# HDSC_HC32L176KATA register map
Vendor: HDSC Co.Ltd; Series: ARMCM0P; File version: 1.2
CPU: CM0 r0p0, little endian, no MPU, no FPU, 3 interrupt priority bits
Registers are 32-bit, read-write, reset 0x0 unless marked. A register's access mark holds for its fields unless they carry their own. Offsets are from the block's base; [hi:lo] are bit positions; {n}, {i} and the like mark numbered series.

## LCD
Base 0x40005C00
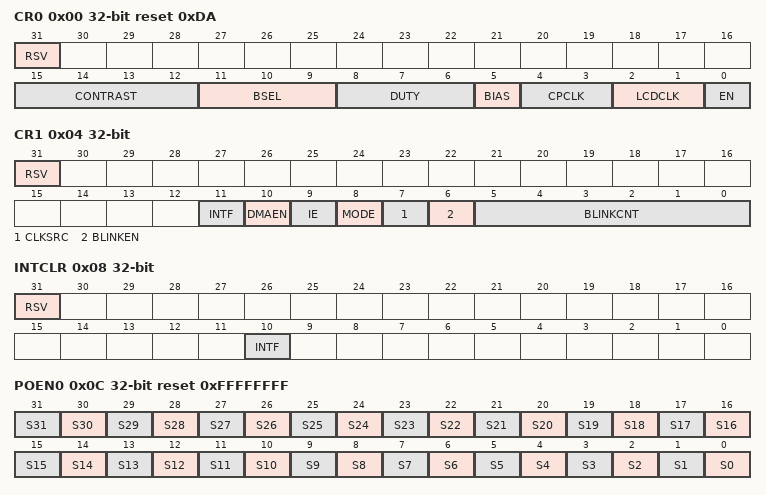
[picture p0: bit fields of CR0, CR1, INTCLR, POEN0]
0x00 CR0 reset 0xDA (reset mask 0xFF)
  [31] RSV, [15:12] CONTRAST, [11:9] BSEL, [8:6] DUTY, [5] BIAS, [4:3] CPCLK, [2:1] LCDCLK, [0] EN
0x04 CR1 (reset mask 0xFFF)
  [31] RSV ro, [11] INTF ro, [10] DMAEN, [9] IE, [8] MODE, [7] CLKSRC, [6] BLINKEN, [5:0] BLINKCNT
0x08 INTCLR wo (reset mask 0x400)
  [31] RSV rw, [10] INTF
0x0C POEN0 reset 0xFFFFFFFF
  [n] S{n} (n=0..31)
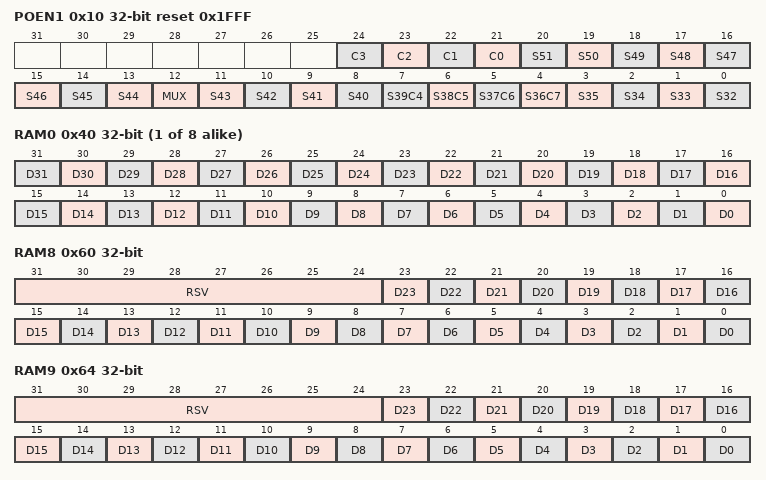
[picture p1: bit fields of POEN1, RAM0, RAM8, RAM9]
0x10 POEN1 reset 0x1FFF (reset mask 0x1FFF)
  [n+21] C{n} (n=0..3), [n-31] S{n} (n=44..51), [12] MUX, [n-32] S{n} (n=40..43), [7] S39C4, [6] S38C5, [5] S37C6, [4] S36C7, [n-32] S{n} (n=32..35)
{0x40+4i} RAM{i} (i=0..7)
  [n] D{n} (n=0..31)
0x60 RAM8 (reset mask 0xFFFFFF)
  [31:24] RSV, [n] D{n} (n=0..23)
0x64 RAM9 (reset mask 0xFFFFFF)
  [31:24] RSV, [n] D{n} (n=0..23)
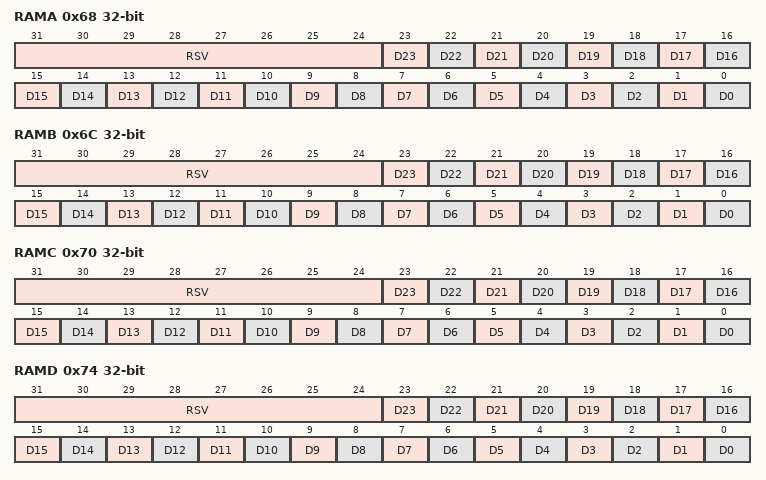
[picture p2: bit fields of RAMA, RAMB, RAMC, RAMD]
0x68 RAMA (reset mask 0xFFFFFF)
  [31:24] RSV, [n] D{n} (n=0..23)
0x6C RAMB (reset mask 0xFFFFFF)
  [31:24] RSV, [n] D{n} (n=0..23)
0x70 RAMC (reset mask 0xFFFFFF)
  [31:24] RSV, [n] D{n} (n=0..23)
0x74 RAMD (reset mask 0xFFFFFF)
  [31:24] RSV, [n] D{n} (n=0..23)
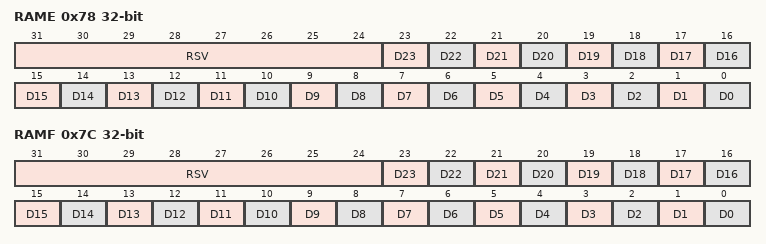
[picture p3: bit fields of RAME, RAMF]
0x78 RAME (reset mask 0xFFFFFF)
  [31:24] RSV, [n] D{n} (n=0..23)
0x7C RAMF (reset mask 0xFFFFFF)
  [31:24] RSV, [n] D{n} (n=0..23)

## LPTIMER0 — desc LPTIMER
Base 0x40000F00
Same registers: LPTIMER1 0x40000F40
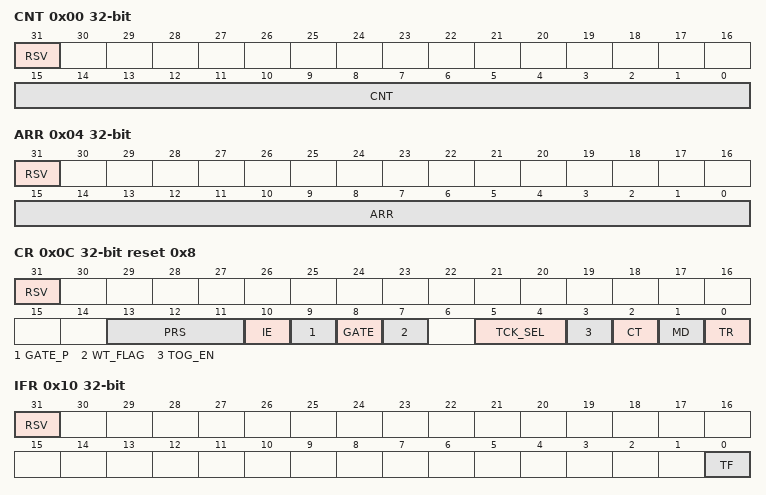
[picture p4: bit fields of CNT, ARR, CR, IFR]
0x00 CNT ro (reset mask 0xFFFF)
  [31] RSV rw, [15:0] CNT
0x04 ARR (reset mask 0xFFFF)
  [31] RSV, [15:0] ARR
0x0C CR reset 0x8 (reset mask 0x3FBF)
  [31] RSV, [13:11] PRS, [10] IE, [9] GATE_P, [8] GATE, [7] WT_FLAG ro, [5:4] TCK_SEL, [3] TOG_EN, [2] CT, [1] MD, [0] TR
0x10 IFR ro (reset mask 0x1)
  [31] RSV rw, [0] TF
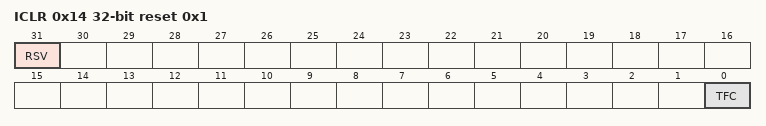
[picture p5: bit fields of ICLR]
0x14 ICLR wo reset 0x1 (reset mask 0x1)
  [31] RSV rw, [0] TFC

## LPUART0 — desc LPUART
Base 0x40000200
Same registers: LPUART1 0x40004000
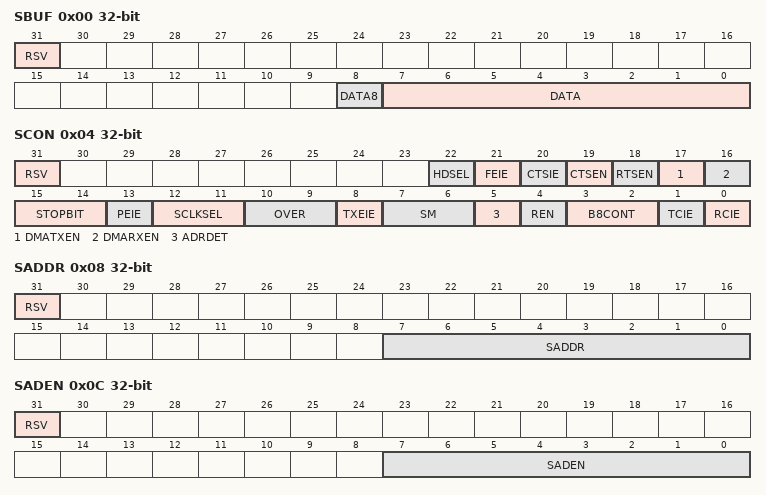
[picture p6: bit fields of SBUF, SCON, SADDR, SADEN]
0x00 SBUF (reset mask 0x1FF)
  [31] RSV, [8] DATA8, [7:0] DATA
0x04 SCON (reset mask 0x7FFFFF)
  [31] RSV, [22] HDSEL, [21] FEIE, [20] CTSIE, [19] CTSEN, [18] RTSEN, [17] DMATXEN, [16] DMARXEN, [15:14] STOPBIT, [13] PEIE, [12:11] SCLKSEL, [10:9] OVER, [8] TXEIE, [7:6] SM, [5] ADRDET, [4] REN, [3:2] B8CONT, [1] TCIE, [0] RCIE
0x08 SADDR (reset mask 0xFF)
  [31] RSV, [7:0] SADDR
0x0C SADEN (reset mask 0xFF)
  [31] RSV, [7:0] SADEN
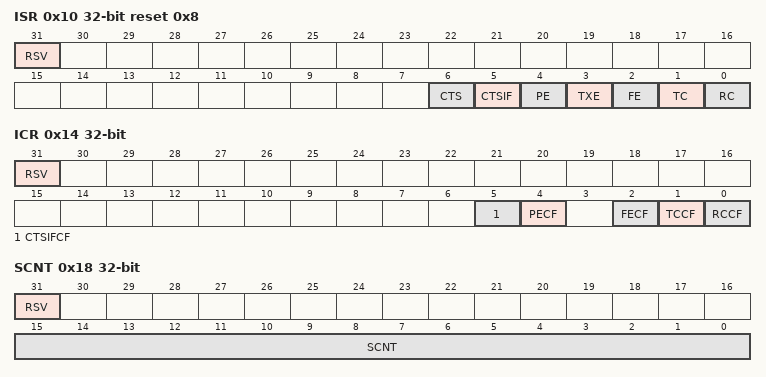
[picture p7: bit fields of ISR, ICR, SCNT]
0x10 ISR ro reset 0x8 (reset mask 0x7F)
  [31] RSV rw, [6] CTS, [5] CTSIF, [4] PE, [3] TXE, [2] FE, [1] TC, [0] RC
0x14 ICR wo (reset mask 0x37)
  [31] RSV rw, [5] CTSIFCF, [4] PECF, [2] FECF, [1] TCCF, [0] RCCF
0x18 SCNT (reset mask 0xFFFF)
  [31] RSV, [15:0] SCNT

## UART0 — desc UART
Base 0x40000000
Same registers: UART1 0x40000100, UART2 0x40006000, UART3 0x40006400
Registers as LPUART0; these are added or differ:
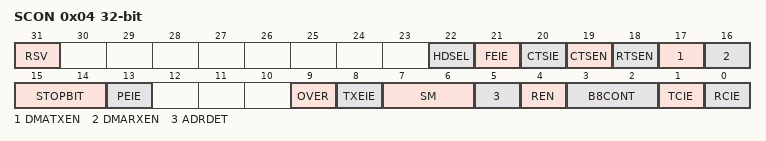
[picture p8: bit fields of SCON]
0x04 SCON (reset mask 0x7FE3FF)
  [31] RSV, [22] HDSEL, [21] FEIE, [20] CTSIE, [19] CTSEN, [18] RTSEN, [17] DMATXEN, [16] DMARXEN, [15:14] STOPBIT, [13] PEIE, [9] OVER, [8] TXEIE, [7:6] SM, [5] ADRDET, [4] REN, [3:2] B8CONT, [1] TCIE, [0] RCIE

## LVD
Base 0x40002400; alternate view of ADC
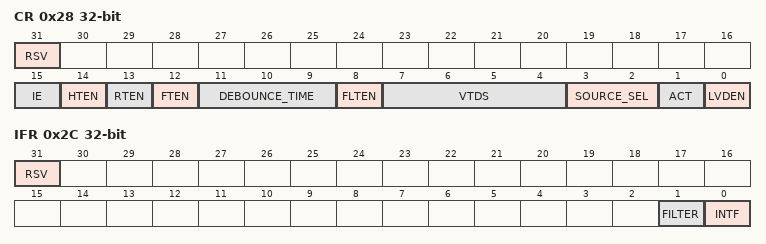
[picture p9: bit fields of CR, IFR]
0x28 CR (reset mask 0xFFFF)
  [31] RSV, [15] IE, [14] HTEN, [13] RTEN, [12] FTEN, [11:9] DEBOUNCE_TIME, [8] FLTEN, [7:4] VTDS, [3:2] SOURCE_SEL, [1] ACT, [0] LVDEN
0x2C IFR (reset mask 0x3)
  [31] RSV, [1] FILTER, [0] INTF

## OPA
Base 0x40002400; alternate view of ADC
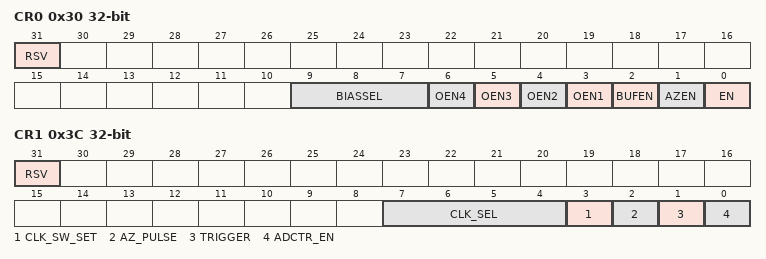
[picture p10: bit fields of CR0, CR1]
0x30 CR0 (reset mask 0xFFF)
  [31] RSV, [9:7] BIASSEL, [n+2] OEN{n} (n=1..4), [2] BUFEN, [1] AZEN, [0] EN
0x3C CR1 (reset mask 0xFF)
  [31] RSV, [7:4] CLK_SEL, [3] CLK_SW_SET, [2] AZ_PULSE, [1] TRIGGER, [0] ADCTR_EN

## PCA
Base 0x40001000
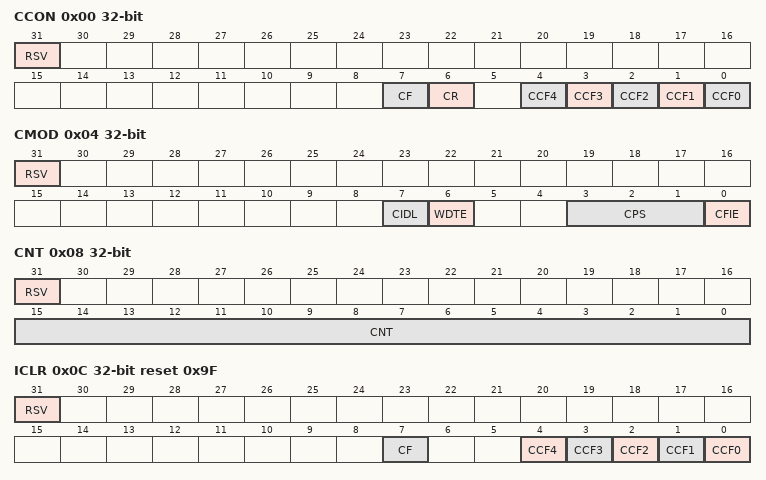
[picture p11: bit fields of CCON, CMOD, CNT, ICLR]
0x00 CCON (reset mask 0xDF)
  [31] RSV, [7] CF, [6] CR, [n] CCF{n} (n=0..4)
0x04 CMOD (reset mask 0xCF)
  [31] RSV, [7] CIDL, [6] WDTE, [3:1] CPS, [0] CFIE
0x08 CNT (reset mask 0xFFFF)
  [31] RSV, [15:0] CNT
0x0C ICLR wo reset 0x9F (reset mask 0x9F)
  [31] RSV rw, [7] CF, [n] CCF{n} (n=0..4)
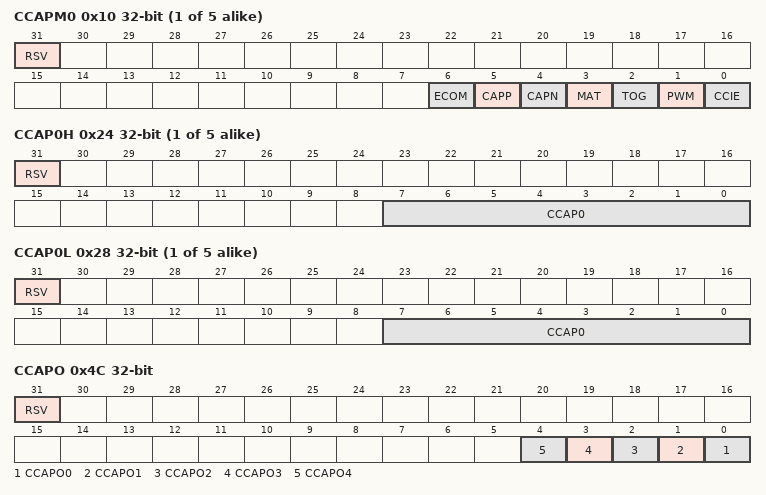
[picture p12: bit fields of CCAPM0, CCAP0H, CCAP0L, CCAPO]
{0x10+4i} CCAPM{i} (reset mask 0x7F) (i=0..4)
  [31] RSV, [6] ECOM, [5] CAPP, [4] CAPN, [3] MAT, [2] TOG, [1] PWM, [0] CCIE
{0x24+8i} CCAP{i}H (reset mask 0xFF) (i=0..4)
  [31] RSV, [7:0] CCAP{i}
{0x28+8i} CCAP{i}L (reset mask 0xFF) (i=0..4)
  [31] RSV, [7:0] CCAP{i}
0x4C CCAPO (reset mask 0x1F)
  [31] RSV, [n] CCAPO{n} (n=0..4)
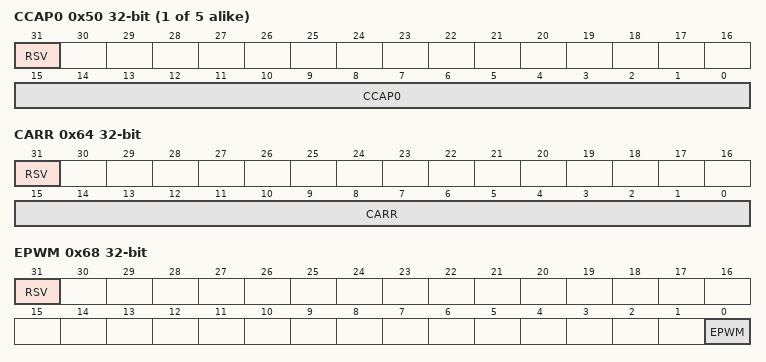
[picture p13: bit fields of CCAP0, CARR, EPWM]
{0x50+4i} CCAP{i} (reset mask 0xFFFF) (i=0..4)
  [31] RSV, [15:0] CCAP{i}
0x64 CARR (reset mask 0xFFFF)
  [31] RSV, [15:0] CARR
0x68 EPWM (reset mask 0x1)
  [31] RSV, [0] EPWM
